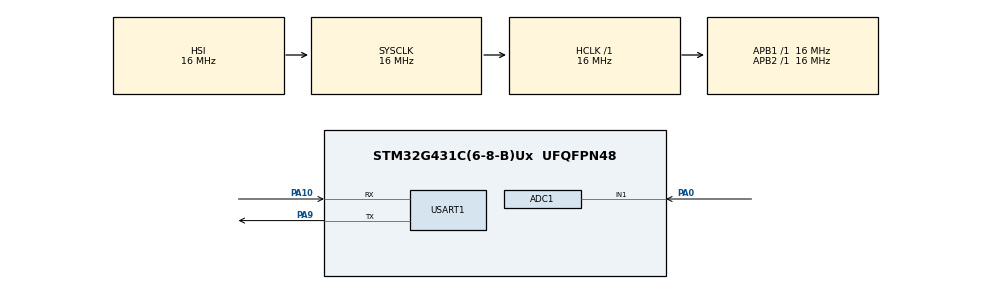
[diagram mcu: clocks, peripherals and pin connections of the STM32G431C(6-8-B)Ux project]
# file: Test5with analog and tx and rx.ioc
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ADC1.Channel-0\#ChannelRegularConversion=ADC_CHANNEL_1
ADC1.NbrOfConversionFlag=1
ADC1.OffsetNumber-0\#ChannelRegularConversion=ADC_OFFSET_NONE
ADC1.Rank-0\#ChannelRegularConversion=1
ADC1.SamplingTime-0\#ChannelRegularConversion=ADC_SAMPLETIME_247CYCLES_5
ADC1.master=1
Mcu.Family=STM32G4
Mcu.Name=STM32G431C(6-8-B)Ux
Mcu.Package=UFQFPN48
NVIC.PriorityGroup=NVIC_PRIORITYGROUP_4
PA0.Mode=IN1-Single-Ended
PA0.Signal=ADC1_IN1
PA10.Mode=Asynchronous
PA10.Signal=USART1_RX
PA13.Mode=Serial_Wire
PA13.Signal=SYS_JTMS-SWDIO
PA14.Mode=Serial_Wire
PA14.Signal=SYS_JTCK-SWCLK
PA9.Mode=Asynchronous
PA9.Signal=USART1_TX
ProjectManager.HeapSize=0x200
ProjectManager.StackSize=0x400
ProjectManager.TargetToolchain=STM32CubeIDE
RCC.AHBFreq_Value=16000000
RCC.APB1Freq_Value=16000000
RCC.APB1TimFreq_Value=16000000
RCC.APB2Freq_Value=16000000
RCC.APB2TimFreq_Value=16000000
RCC.CortexFreq_Value=16000000
RCC.EXTERNAL_CLOCK_VALUE=12288000
RCC.HCLKFreq_Value=16000000
RCC.HSE_VALUE=8000000
RCC.HSI48_VALUE=48000000
RCC.HSI_VALUE=16000000
RCC.LSE_VALUE=32768
RCC.SYSCLKFreq_VALUE=16000000
RCC.USBFreq_Value=64000000
RCC.VCOOutputFreq_Value=128000000
USART1.VirtualMode-Asynchronous=VM_ASYNC
VP_SYS_VS_DBSignals.Mode=DisableDeadBatterySignals
board=custom

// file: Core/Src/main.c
/* USER CODE BEGIN Header */
/**
  ******************************************************************************
  * @file           : main.c
  * @brief          : Main program body
  ******************************************************************************
  * @attention
  *
  * Copyright (c) 2026 STMicroelectronics.
  * All rights reserved.
  *
  * This software is licensed under terms that can be found in the LICENSE file
  * in the root directory of this software component.
  * If no LICENSE file comes with this software, it is provided AS-IS.
  *
  ******************************************************************************
  */
/* USER CODE END Header */
#include "main.h"

/* USER CODE BEGIN Includes */
#include "adc_methods.h"
#include "ct_sensor.h"
/* USER CODE END Includes */

/* USER CODE BEGIN PD */
/*
 * ============= ADC METHOD SELECTOR =============
 * Uncomment ONE of the lines below to choose your ADC method:
 *   ADC_USE_OVERSAMPLED  -> 14-bit oversampling + decimation (finer resolution)
 *   ADC_USE_AVERAGED     -> 12-bit software averaging (noise reduction)
 *   ADC_USE_CT_RMS       -> CT sensor true RMS current measurement
 */
// #define ADC_USE_OVERSAMPLED
#define ADC_USE_CT_RMS
// #define ADC_USE_CT_RMS

#define VREF  3.3f   // Measure your 3.3V pin with a multimeter and put the real value here
/* USER CODE END PD */

ADC_HandleTypeDef hadc1;

UART_HandleTypeDef huart1;

/* USER CODE BEGIN PV */
volatile uint16_t adc_raw        = 0;     // Raw ADC count (watch in Live Expressions)
volatile float    adc_voltage    = 0.0f;  // Converted voltage in volts
volatile float    current_rms    = 0.0f;  // RMS current in Amps (CT mode)
volatile float    power_apparent = 0.0f;  // Apparent power in Watts (CT mode)
/* USER CODE END PV */

void SystemClock_Config(void);
static void MX_GPIO_Init(void);
static void MX_ADC1_Init(void);
static void MX_USART1_UART_Init(void);

int main(void)
{

  /* MCU Configuration--------------------------------------------------------*/

  /* Reset of all peripherals, Initializes the Flash interface and the Systick. */
  HAL_Init();

  /* Configure the system clock */
  SystemClock_Config();

  /* Initialize all configured peripherals */
  MX_GPIO_Init();
  MX_ADC1_Init();
  MX_USART1_UART_Init();
  /* USER CODE BEGIN 2 */
  HAL_ADCEx_Calibration_Start(&hadc1, ADC_SINGLE_ENDED);

#ifdef ADC_USE_CT_RMS
  /* --- Your sensor: 1V RMS = 30A → use direct mapping --- */
  CT_Config_t ct_cfg = CT_GetDirectMapConfig(VREF, 30.0f);

  /* Calibrated from real measurement: 0.413A actual / 48.095A raw = 0.00859 */
  ct_cfg.cal_factor = 0.00859f;

  /* Optional tweaks: */
  // ct_cfg.mains_voltage = 230.0f;  // Change to 120.0f for US
  // ct_cfg.num_samples   = 1000;    // ~2 cycles at 50Hz

  /* Alternative: for current-output CTs (e.g. SCT-013-000), use this instead:
   *   CT_Config_t ct_cfg = CT_GetDefaultConfig(VREF);
   *   ct_cfg.ct_ratio    = 2000.0f;
   *   ct_cfg.burden_ohms = 33.0f;
   */

  /* Calibrate DC bias (ensure NO current is flowing through CT at startup) */
  CT_CalibrateBias(&hadc1, &ct_cfg);
#endif
  /* USER CODE END 2 */

  /* Infinite loop */
  while (1)
  {

    /* USER CODE BEGIN 3 */

#ifdef ADC_USE_CT_RMS
    /* ---- CT Sensor RMS Mode ---- */
    CT_Result_t ct_result = CT_ReadRMS(&hadc1, &ct_cfg);

    /* Update globals for Live Expressions */
    current_rms    = ct_result.i_rms;
    power_apparent = ct_result.power_apparent;
    adc_voltage    = ct_result.v_rms_sensor;

    /* Send to ESP32 */
    CT_SendResult(&huart1, &ct_result);

#elif defined(ADC_USE_OVERSAMPLED)
    /* ---- 14-bit Oversampling Mode ---- */
    ADC_Result_t result = ADC_ReadOversampled(&hadc1, VREF);
    adc_raw     = result.raw;
    adc_voltage = result.voltage;
    ADC_SendResult(&huart1, &result);

#else
    /* ---- 12-bit Averaging Mode (default) ---- */
    ADC_Result_t result = ADC_ReadAveraged(&hadc1, VREF);
    adc_raw     = result.raw;
    adc_voltage = result.voltage;
    ADC_SendResult(&huart1, &result);

#endif

    HAL_Delay(100);
  }
  /* USER CODE END 3 */
}

void SystemClock_Config(void)
{
  RCC_OscInitTypeDef RCC_OscInitStruct = {0};
  RCC_ClkInitTypeDef RCC_ClkInitStruct = {0};

  /** Configure the main internal regulator output voltage
  */
  HAL_PWREx_ControlVoltageScaling(PWR_REGULATOR_VOLTAGE_SCALE1);

  /** Initializes the RCC Oscillators according to the specified parameters
  * in the RCC_OscInitTypeDef structure.
  */
  RCC_OscInitStruct.OscillatorType = RCC_OSCILLATORTYPE_HSI;
  RCC_OscInitStruct.HSIState = RCC_HSI_ON;
  RCC_OscInitStruct.HSICalibrationValue = RCC_HSICALIBRATION_DEFAULT;
  RCC_OscInitStruct.PLL.PLLState = RCC_PLL_NONE;
  if (HAL_RCC_OscConfig(&RCC_OscInitStruct) != HAL_OK)
  {
    Error_Handler();
  }

  /** Initializes the CPU, AHB and APB buses clocks
  */
  RCC_ClkInitStruct.ClockType = RCC_CLOCKTYPE_HCLK|RCC_CLOCKTYPE_SYSCLK
                              |RCC_CLOCKTYPE_PCLK1|RCC_CLOCKTYPE_PCLK2;
  RCC_ClkInitStruct.SYSCLKSource = RCC_SYSCLKSOURCE_HSI;
  RCC_ClkInitStruct.AHBCLKDivider = RCC_SYSCLK_DIV1;
  RCC_ClkInitStruct.APB1CLKDivider = RCC_HCLK_DIV1;
  RCC_ClkInitStruct.APB2CLKDivider = RCC_HCLK_DIV1;

  if (HAL_RCC_ClockConfig(&RCC_ClkInitStruct, FLASH_LATENCY_0) != HAL_OK)
  {
    Error_Handler();
  }
}

static void MX_ADC1_Init(void)
{

  ADC_MultiModeTypeDef multimode = {0};
  ADC_ChannelConfTypeDef sConfig = {0};

  /** Common config
  */
  hadc1.Instance = ADC1;
  hadc1.Init.ClockPrescaler = ADC_CLOCK_SYNC_PCLK_DIV2;
  hadc1.Init.Resolution = ADC_RESOLUTION_12B;
  hadc1.Init.DataAlign = ADC_DATAALIGN_RIGHT;
  hadc1.Init.GainCompensation = 0;
  hadc1.Init.ScanConvMode = ADC_SCAN_DISABLE;
  hadc1.Init.EOCSelection = ADC_EOC_SINGLE_CONV;
  hadc1.Init.LowPowerAutoWait = DISABLE;
  hadc1.Init.ContinuousConvMode = DISABLE;
  hadc1.Init.NbrOfConversion = 1;
  hadc1.Init.DiscontinuousConvMode = DISABLE;
  hadc1.Init.ExternalTrigConv = ADC_SOFTWARE_START;
  hadc1.Init.ExternalTrigConvEdge = ADC_EXTERNALTRIGCONVEDGE_NONE;
  hadc1.Init.DMAContinuousRequests = DISABLE;
  hadc1.Init.Overrun = ADC_OVR_DATA_PRESERVED;
  hadc1.Init.OversamplingMode = DISABLE;
  if (HAL_ADC_Init(&hadc1) != HAL_OK)
  {
    Error_Handler();
  }

  /** Configure the ADC multi-mode
  */
  multimode.Mode = ADC_MODE_INDEPENDENT;
  if (HAL_ADCEx_MultiModeConfigChannel(&hadc1, &multimode) != HAL_OK)
  {
    Error_Handler();
  }

  /** Configure Regular Channel
  */
  sConfig.Channel = ADC_CHANNEL_1;
  sConfig.Rank = ADC_REGULAR_RANK_1;
  sConfig.SamplingTime = ADC_SAMPLETIME_247CYCLES_5;
  sConfig.SingleDiff = ADC_SINGLE_ENDED;
  sConfig.OffsetNumber = ADC_OFFSET_NONE;
  sConfig.Offset = 0;
  if (HAL_ADC_ConfigChannel(&hadc1, &sConfig) != HAL_OK)
  {
    Error_Handler();
  }

}

static void MX_USART1_UART_Init(void)
{

  huart1.Instance = USART1;
  huart1.Init.BaudRate = 115200;
  huart1.Init.WordLength = UART_WORDLENGTH_8B;
  huart1.Init.StopBits = UART_STOPBITS_1;
  huart1.Init.Parity = UART_PARITY_NONE;
  huart1.Init.Mode = UART_MODE_TX_RX;
  huart1.Init.HwFlowCtl = UART_HWCONTROL_NONE;
  huart1.Init.OverSampling = UART_OVERSAMPLING_16;
  huart1.Init.OneBitSampling = UART_ONE_BIT_SAMPLE_DISABLE;
  huart1.Init.ClockPrescaler = UART_PRESCALER_DIV1;
  huart1.AdvancedInit.AdvFeatureInit = UART_ADVFEATURE_NO_INIT;
  if (HAL_UART_Init(&huart1) != HAL_OK)
  {
    Error_Handler();
  }
  if (HAL_UARTEx_SetTxFifoThreshold(&huart1, UART_TXFIFO_THRESHOLD_1_8) != HAL_OK)
  {
    Error_Handler();
  }
  if (HAL_UARTEx_SetRxFifoThreshold(&huart1, UART_RXFIFO_THRESHOLD_1_8) != HAL_OK)
  {
    Error_Handler();
  }
  if (HAL_UARTEx_DisableFifoMode(&huart1) != HAL_OK)
  {
    Error_Handler();
  }

}

static void MX_GPIO_Init(void)
{

  /* GPIO Ports Clock Enable */
  __HAL_RCC_GPIOA_CLK_ENABLE();

}

void Error_Handler(void)
{
  __disable_irq();
  while (1)
  {
  }
}
